# LPC408x_7x register map
File version: 0.7
CPU: CM4 r0p0, little endian, no MPU, no FPU, 3 interrupt priority bits
Registers are 32-bit, read-write, reset 0x0 unless marked. A register's access mark holds for its fields unless they carry their own. Offsets are from the block's base; [hi:lo] are bit positions; {n}, {i} and the like mark numbered series; 'fields as' and 'values as' point back to an identical list.

## IOCON (part 2 of 2) — IOCON pin configuration
Base 0x4002C000
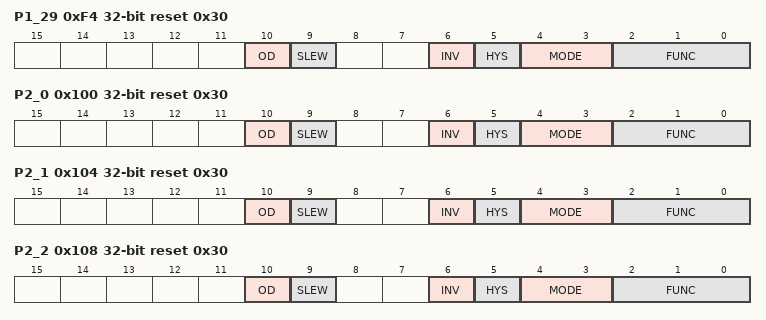
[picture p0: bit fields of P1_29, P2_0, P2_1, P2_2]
0xF4 P1_29 reset 0x30 — I/O configuration register for pin P1[29]
  [10] OD — Open-drain mode.
    0=DISABLE_; 1=OPEN_DRAIN_MODE_ENAB (Open-drain mode enabled. This is not a true open-drain mode. Input cannot be pulled up above VDD.)
  [9] SLEW — Driver slew rate
    0=STANDARD (Standard mode, output slew rate control is enabled. More outputs can be switched simultaneously.); 1=FAST (Fast mode, slew rate control is disabled. Refer to the appropriate specific device data sheet for details.)
  [6] INV — Invert input
    0=INPUT_NOT_INVERTED_ (Input not inverted (HIGH on pin reads as 1, LOW on pin reads as 0).); 1=INPUT_INVERTED_HIGH (Input inverted (HIGH on pin reads as 0, LOW on pin reads as 1).)
  [5] HYS — Hysteresis.
    0=DISABLE_; 1=ENABLE_
  [4:3] MODE — Selects function mode (on-chip pull-up/pull-down resistor control).
    0=INACTIVE_NO_PULL_DO (Inactive (no pull-down/pull-up resistor enabled).); 1=PULL_DOWN_RESISTOR_E (Pull-down resistor enabled.); 2=PULL_UP_RESISTOR_ENA (Pull-up resistor enabled.); 3=REPEATER_MODE_
  [2:0] FUNC — Selects pin function for pin P1[29]
    0=P1_29 (General purpose digital input/output pin.); 1=USB_SDA1 (USB port 1 I2C serial data (OTG transceiver).); 2=PWM1_CAP1 (Capture input for PWM1, channel 1.); 3=T0_MAT1 (Match output for Timer 0, channel 1.); 4=MC_2B (Motor control PWM channel 2, output B.); 5=U4_TXD (Transmitter output for USART4 (input/output in smart card mode).); 6=LCD_VD_15 (LCD data.); 7=LCD_VD_23 (LCD data.)
0xF8 P1_30 reset not defined — I/O configuration register for pin P1[30]
  [2:0] FUNC — Selects pin function for pin P1[30]
    0=P1_30 (General purpose digital input/output pin.); 1=USB_PWRD2 (Power Status for USB port 2.); 2=USB_VBUS (Monitors the presence of USB bus power.This signal must be HIGH for USB reset to occur.); 3=ADC0_IN_4 (A/D converter 0, input 4. When configured as an ADC input, the digital function of the pin must be disabled.); 4=I2C0_SDA (I2C0 data input/output (this pin does not use a specialized I2C pad.); 5=U3_OE (RS-485/EIA-485 output enable signal for UART3.)
0xFC P1_31 reset not defined — I/O configuration register for pin P1[31]
  [2:0] FUNC — Selects pin function for pin P1[31]
    0=P1_31 (General purpose digital input/output pin.); 1=USB_OVRCR2 (Over-Current status for USB port 2.); 2=SSP1_SCK (Serial Clock for SSP1.); 3=ADC0_IN_5 (A/D converter 0, input 5. When configured as an ADC input, the digital function of the pin must be disabled.); 4=I2C0_SCL (I2C0 clock input/output (this pin does not use a specialized I2C pad.)
0x100 P2_0 reset 0x30 — I/O configuration register for pin P2[0]
  [10] OD — Open-drain mode.
    values as P1_29.OD
  [9] SLEW — Driver slew rate
    values as P1_29.SLEW
  [6] INV — Invert input
    values as P1_29.INV
  [5] HYS — Hysteresis.
    0=DISABLE_; 1=ENABLE_
  [4:3] MODE — Selects function mode (on-chip pull-up/pull-down resistor control).
    values as P1_29.MODE
  [2:0] FUNC — Selects pin function for pin P2[0]
    0=P2_0 (General purpose digital input/output pin.); 1=PWM1_1 (Pulse Width Modulator 1, channel 1 output.); 2=U1_TXD (Transmitter output for UART1.); 7=LCD_PWR (LCD panel power enable.)
0x104 P2_1 reset 0x30 — I/O configuration register for pin P2[1]
  [10] OD — Open-drain mode.
    values as P1_29.OD
  [9] SLEW — Driver slew rate
    values as P1_29.SLEW
  [6] INV — Invert input
    values as P1_29.INV
  [5] HYS — Hysteresis.
    0=DISABLE_; 1=ENABLE_
  [4:3] MODE — Selects function mode (on-chip pull-up/pull-down resistor control).
    values as P1_29.MODE
  [2:0] FUNC — Selects pin function for pin P2[1]
    0=P2_1 (General purpose digital input/output pin.); 1=PWM1_2 (Pulse Width Modulator 1, channel 2 output.); 2=U1_RXD (Receiver input for UART1.); 7=LCD_LE (Line end signal.)
0x108 P2_2 reset 0x30 — I/O configuration register for pin P2[2]
  [10] OD — Open-drain mode.
    values as P1_29.OD
  [9] SLEW — Driver slew rate
    values as P1_29.SLEW
  [6] INV — Invert input
    values as P1_29.INV
  [5] HYS — Hysteresis.
    0=DISABLE_; 1=ENABLE_
  [4:3] MODE — Selects function mode (on-chip pull-up/pull-down resistor control).
    values as P1_29.MODE
  [2:0] FUNC — Selects pin function for pin P2[2]
    0=P2_2 (General purpose digital input/output pin.); 1=PWM1_3 (Pulse Width Modulator 1, channel 3 output.); 2=U1_CTS (Clear to Send input for UART1.); 3=T2_MAT3 (Match output for Timer 2, channel 3.); 5=TRACEDATA_3 (Trace data, bit 3.); 7=LCD_DCLK (LCD panel clock.)
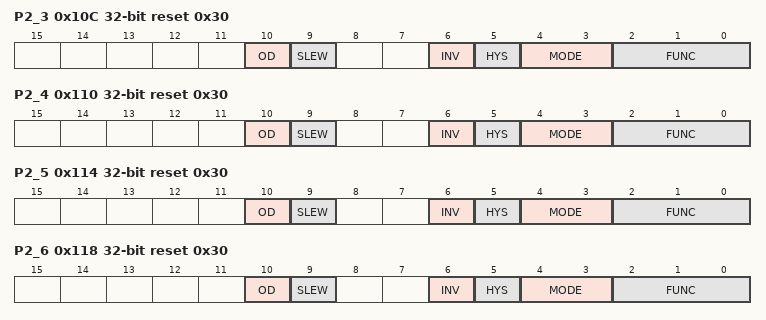
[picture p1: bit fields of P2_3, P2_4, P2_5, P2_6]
0x10C P2_3 reset 0x30 — I/O configuration register for pin P2[3]
  [10] OD — Open-drain mode.
    values as P1_29.OD
  [9] SLEW — Driver slew rate
    values as P1_29.SLEW
  [6] INV — Invert input
    values as P1_29.INV
  [5] HYS — Hysteresis.
    0=DISABLE_; 1=ENABLE_
  [4:3] MODE — Selects function mode (on-chip pull-up/pull-down resistor control).
    values as P1_29.MODE
  [2:0] FUNC — Selects pin function for pin P2[3]
    0=P2_3 (General purpose digital input/output pin.); 1=PWM1_4 (Pulse Width Modulator 1, channel 4 output.); 2=U1_DCD (Data Carrier Detect input for UART1.); 3=T2_MAT2 (Match output for Timer 2, channel 2.); 5=TRACEDATA_2 (Trace data, bit 2.); 7=LCD_FP (Frame pulse (STN). Vertical synchronization pulse (TFT).)
0x110 P2_4 reset 0x30 — I/O configuration register for pin P2[4]
  [10] OD — Open-drain mode.
    values as P1_29.OD
  [9] SLEW — Driver slew rate
    values as P1_29.SLEW
  [6] INV — Invert input
    values as P1_29.INV
  [5] HYS — Hysteresis.
    0=DISABLE_; 1=ENABLE_
  [4:3] MODE — Selects function mode (on-chip pull-up/pull-down resistor control).
    values as P1_29.MODE
  [2:0] FUNC — Selects pin function for pin P2[4]
    0=P2_4 (General purpose digital input/output pin.); 1=PWM1_5 (Pulse Width Modulator 1, channel 5 output.); 2=U1_DSR (Data Set Ready input for UART1.); 3=T2_MAT1 (Match output for Timer 2, channel 1.); 5=TRACEDATA_1 (Trace data, bit 1.); 7=LCD_ENAB_M (STN AC bias drive or TFT data enable output.)
0x114 P2_5 reset 0x30 — I/O configuration register for pin P2[5]
  [10] OD — Open-drain mode.
    values as P1_29.OD
  [9] SLEW — Driver slew rate
    values as P1_29.SLEW
  [6] INV — Invert input
    values as P1_29.INV
  [5] HYS — Hysteresis.
    0=DISABLE_; 1=ENABLE_
  [4:3] MODE — Selects function mode (on-chip pull-up/pull-down resistor control).
    values as P1_29.MODE
  [2:0] FUNC — Selects pin function for pin P2[5]
    0=P2_5 (General purpose digital input/output pin.); 1=PWM1_6 (Pulse Width Modulator 1, channel 6 output.); 2=U1_DTR (Data Terminal Ready output for UART1. Can also be configured to be an RS-485/EIA-485 output enable signal for UART1.); 3=T2_MAT0 (Match output for Timer 2, channel 0.); 5=TRACEDATA_0 (Trace data, bit 0.); 7=LCD_LP (Line synchronization pulse (STN). Horizontal synchronization pulse (TFT).)
0x118 P2_6 reset 0x30 — I/O configuration register for pin P2[6]
  [10] OD — Open-drain mode.
    values as P1_29.OD
  [9] SLEW — Driver slew rate
    values as P1_29.SLEW
  [6] INV — Invert input
    values as P1_29.INV
  [5] HYS — Hysteresis.
    0=DISABLE_; 1=ENABLE_
  [4:3] MODE — Selects function mode (on-chip pull-up/pull-down resistor control).
    values as P1_29.MODE
  [2:0] FUNC — Selects pin function for pin P2[6]
    0=P2_6 (General purpose digital input/output pin.); 1=PWM1_CAP0 (Capture input for PWM1, channel 0.); 2=U1_RI (Ring Indicator input for UART1.); 3=T2_CAP0 (Capture input for Timer 2, channel 0.); 4=U2_OE (RS-485/EIA-485 output enable signal for UART2.); 5=TRACECLK (Trace clock.); 6=LCD_VD_0 (LCD data.); 7=LCD_VD_4 (LCD data.)
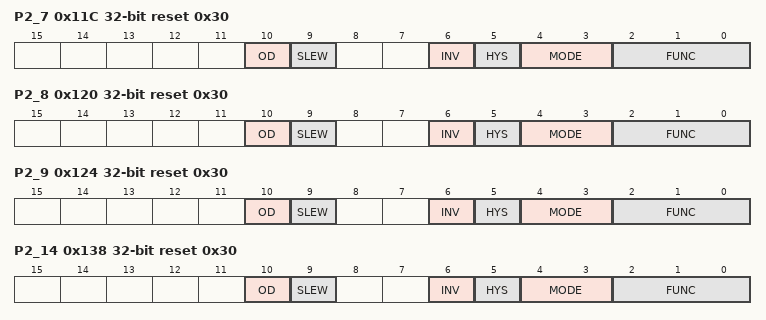
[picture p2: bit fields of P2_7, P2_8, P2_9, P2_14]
0x11C P2_7 reset 0x30 — I/O configuration register for pin P2[7]
  [10] OD — Open-drain mode.
    values as P1_29.OD
  [9] SLEW — Driver slew rate
    values as P1_29.SLEW
  [6] INV — Invert input
    values as P1_29.INV
  [5] HYS — Hysteresis.
    0=DISABLE_; 1=ENABLE_
  [4:3] MODE — Selects function mode (on-chip pull-up/pull-down resistor control).
    values as P1_29.MODE
  [2:0] FUNC — Selects pin function for pin P2[7]
    0=P2_7 (General purpose digital input/output pin.); 1=CAN_RD2 (CAN2 receiver input.); 2=U1_RTS (Request to Send output for UART1. Can also be configured to be an RS-485/EIA-485 output enable signal for UART1.); 5=SPIFI_CS (Chip select output for SPIFI.); 6=LCD_VD_1 (LCD data.); 7=LCD_VD_5 (LCD data.)
0x120 P2_8 reset 0x30 — I/O configuration register for pin P2[8]
  [10] OD — Open-drain mode.
    values as P1_29.OD
  [9] SLEW — Driver slew rate
    values as P1_29.SLEW
  [6] INV — Invert input
    values as P1_29.INV
  [5] HYS — Hysteresis.
    0=DISABLE_; 1=ENABLE_
  [4:3] MODE — Selects function mode (on-chip pull-up/pull-down resistor control).
    values as P1_29.MODE
  [2:0] FUNC — Selects pin function for pin P2[8]
    0=P2_8 (General purpose digital input/output pin.); 1=CAN_TD2 (CAN2 transmitter output.); 2=U2_TXD (Transmitter output for UART2.); 3=U1_CTS (Clear to Send input for UART1.); 4=ENET_MDC (Ethernet MIIM clock.); 6=LCD_VD_2 (LCD data.); 7=LCD_VD_6 (LCD data.)
0x124 P2_9 reset 0x30 — I/O configuration register for pin P2[9]
  [10] OD — Open-drain mode.
    values as P1_29.OD
  [9] SLEW — Driver slew rate
    values as P1_29.SLEW
  [6] INV — Invert input
    values as P1_29.INV
  [5] HYS — Hysteresis.
    0=DISABLE_; 1=ENABLE_
  [4:3] MODE — Selects function mode (on-chip pull-up/pull-down resistor control).
    values as P1_29.MODE
  [2:0] FUNC — Selects pin function for pin P2[9]
    0=P2_9 (General purpose digital input/output pin.); 1=USB_CONNECT1 (USB1 SoftConnect control. Signal used to switch an external 1.5 kW resistor under the software control. Used with the SoftConnect USB feature.); 2=U2_RXD (Receiver input for UART2.); 3=U4_RXD (Receiver input for USART4.); 4=ENET_MDIO (Ethernet MIIM data input and output.); 6=LCD_VD_3 (LCD data.); 7=LCD_VD_7 (LCD data.)
0x128 P2_10 reset not defined — I/O configuration register for pin P2[10]
  [2:0] FUNC — Selects pin function for pin P2[10]
    0=P2_10 (General purpose digital input/output pin. This pin includes a 5 ns input glitch filter.A LOW on this pin while RESET is LOW forces the on-chip boot loader to take over control of the part after a reset and go into ISP mode.); 1=EINT0 (External interrupt 0 input.); 2=NMI (Non-maskable interrupt input.)
0x12C P2_11 reset not defined — I/O configuration register for pin P2[11]
  [2:0] FUNC — Selects pin function for pin P2[11]
    0=P2_11 (General purpose digital input/output pin. This pin includes a 5 ns input glitch filter.); 1=EINT1 (External interrupt 1 input.); 2=SD_DAT_1 (Data line 1 for SD card interface.); 3=I2S_TX_SCK (Transmit Clock. It is driven by the master and received by the slave. Corresponds to the signal SCK in the I2S-bus specification.); 7=LCD_CLKIN (LCD clock.)
0x130 P2_12 reset not defined — I/O configuration register for pin P2[12]
  [2:0] FUNC — Selects pin function for pin P2[12]
    0=P2_12 (General purpose digital input/output pin. This pin includes a 5 ns input glitch filter.); 1=EINT2 (External interrupt 2 input.); 2=SD_DAT_2 (Data line 2 for SD card interface.); 3=I2S_TX_WS (Transmit Word Select. It is driven by the master and received by the slave. Corresponds to the signal WS in the I2S-bus specification.); 4=LCD_VD_4 (LCD data.); 5=LCD_VD_3 (LCD data.); 6=LCD_VD_8 (LCD data.); 7=LCD_VD_18 (LCD data.)
0x134 P2_13 reset not defined — I/O configuration register for pin P2[13]
  [2:0] FUNC — Selects pin function for pin P2[13]
    0=P2_13 (General purpose digital input/output pin. This pin includes a 5 ns input glitch filter.); 1=EINT3 (External interrupt 3 input.); 2=SD_DAT_3 (Data line 3 for SD card interface.); 3=I2S_TX_SDA (Transmit data. It is driven by the transmitter and read by the receiver. Corresponds to the signal SD in the I2S-bus specification.); 5=LCD_VD_5 (LCD data.); 6=LCD_VD_9 (LCD data.); 7=LCD_VD_19 (LCD data.)
0x138 P2_14 reset 0x30 — I/O configuration register for pin P2[14]
  [10] OD — Open-drain mode.
    values as P1_29.OD
  [9] SLEW — Driver slew rate
    values as P1_29.SLEW
  [6] INV — Invert input
    values as P1_29.INV
  [5] HYS — Hysteresis.
    0=DISABLE_; 1=ENABLE_
  [4:3] MODE — Selects function mode (on-chip pull-up/pull-down resistor control).
    values as P1_29.MODE
  [2:0] FUNC — Selects pin function for pin P2[14]
    0=P2_14 (General purpose digital input/output pin.); 1=EMC_CS2 (LOW active Chip Select 2 signal.); 2=I2C1_SDA (I2C1 data input/output (this pin does not use a specialized I2C pad).); 3=T2_CAP0 (Capture input for Timer 2, channel 0.)
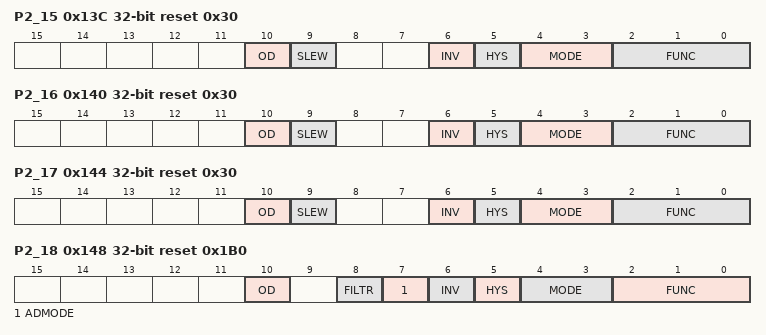
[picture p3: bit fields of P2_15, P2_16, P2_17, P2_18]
0x13C P2_15 reset 0x30 — I/O configuration register for pin P2[15]
  [10] OD — Open-drain mode.
    values as P1_29.OD
  [9] SLEW — Driver slew rate
    values as P1_29.SLEW
  [6] INV — Invert input
    values as P1_29.INV
  [5] HYS — Hysteresis.
    0=DISABLE_; 1=ENABLE_
  [4:3] MODE — Selects function mode (on-chip pull-up/pull-down resistor control).
    values as P1_29.MODE
  [2:0] FUNC — Selects pin function for pin P2[15]
    0=P2_15 (General purpose digital input/output pin.); 1=EMC_CS3 (LOW active Chip Select 3 signal.); 2=I2C1_SCL (I2C1 clock input/output (this pin does not use a specialized I2C pad).); 3=T2_CAP1 (Capture input for Timer 2, channel 1.)
0x140 P2_16 reset 0x30 — I/O configuration register for pin P2[16]
  [10] OD — Open-drain mode.
    values as P1_29.OD
  [9] SLEW — Driver slew rate
    values as P1_29.SLEW
  [6] INV — Invert input
    values as P1_29.INV
  [5] HYS — Hysteresis.
    0=DISABLE_; 1=ENABLE_
  [4:3] MODE — Selects function mode (on-chip pull-up/pull-down resistor control).
    values as P1_29.MODE
  [2:0] FUNC — Selects pin function for pin P2[16]
    0=P2_16 (General purpose digital input/output pin.); 1=EMC_CAS (LOW active SDRAM Column Address Strobe.)
0x144 P2_17 reset 0x30 — I/O configuration register for pin P2[17]
  [10] OD — Open-drain mode.
    values as P1_29.OD
  [9] SLEW — Driver slew rate
    values as P1_29.SLEW
  [6] INV — Invert input
    values as P1_29.INV
  [5] HYS — Hysteresis.
    0=DISABLE_; 1=ENABLE_
  [4:3] MODE — Selects function mode (on-chip pull-up/pull-down resistor control).
    values as P1_29.MODE
  [2:0] FUNC — Selects pin function for pin P2[17]
    0=P2_17 (General purpose digital input/output pin.); 1=EMC_RAS (LOW active SDRAM Row Address Strobe.)
0x148 P2_18 reset 0x1B0 — I/O configuration register for pin P2[18]
  [10] OD — Open-drain mode.
    0=DISABLE_; 1=OPEN_DRAIN_MODE_ENAB (Open-drain mode enabled. This is not a true open-drain mode.)
  [8] FILTR — Selects 10 ns input glitch filter.
    0=FILTER_DISABLED_; 1=FILTER_ENABLED_
  [7] ADMODE — Selects Analog/Digital mode.
    0=ANALOG_INPUT_MODE_; 1=DIGITAL_FUNCTIONAL_M (Digital functional mode.)
  [6] INV — Invert input
    values as P1_29.INV
  [5] HYS — Hysteresis.
    0=DISABLE_; 1=ENABLE_
  [4:3] MODE — Selects function mode (on-chip pull-up/pull-down resistor control).
    values as P1_29.MODE
  [2:0] FUNC — Selects pin function for pin P2[18]
    0=P2_18 (General purpose digital input/output pin.); 1=EMC_CLK_0 (SDRAM clock 0.)
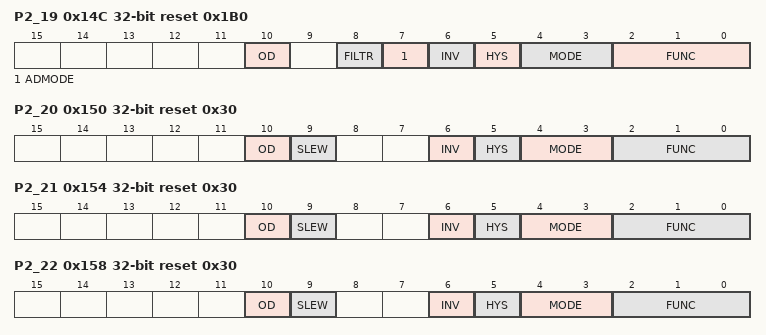
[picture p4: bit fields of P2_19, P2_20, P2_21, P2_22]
0x14C P2_19 reset 0x1B0 — I/O configuration register for pin P2[19]
  [10] OD — Open-drain mode.
    values as P2_18.OD
  [8] FILTR — Selects 10 ns input glitch filter.
    0=FILTER_DISABLED_; 1=FILTER_ENABLED_
  [7] ADMODE — Selects Analog/Digital mode.
    values as P2_18.ADMODE
  [6] INV — Invert input
    values as P1_29.INV
  [5] HYS — Hysteresis.
    0=DISABLE_; 1=ENABLE_
  [4:3] MODE — Selects function mode (on-chip pull-up/pull-down resistor control).
    values as P1_29.MODE
  [2:0] FUNC — Selects pin function for pin P2[19]
    0=P2_19 (General purpose digital input/output pin.); 1=EMC_CLK_1 (SDRAM clock 1.)
0x150 P2_20 reset 0x30 — I/O configuration register for pin P2[20]
  [10] OD — Open-drain mode.
    values as P1_29.OD
  [9] SLEW — Driver slew rate
    values as P1_29.SLEW
  [6] INV — Invert input
    values as P1_29.INV
  [5] HYS — Hysteresis.
    0=DISABLE_; 1=ENABLE_
  [4:3] MODE — Selects function mode (on-chip pull-up/pull-down resistor control).
    values as P1_29.MODE
  [2:0] FUNC — Selects pin function for pin P2[20]
    0=P2_20 (General purpose digital input/output pin.); 1=EMC_DYCS0 (SDRAM chip select 0.)
0x154 P2_21 reset 0x30 — I/O configuration register for pin P2[21]
  [10] OD — Open-drain mode.
    values as P1_29.OD
  [9] SLEW — Driver slew rate
    values as P1_29.SLEW
  [6] INV — Invert input
    values as P1_29.INV
  [5] HYS — Hysteresis.
    0=DISABLE_; 1=ENABLE_
  [4:3] MODE — Selects function mode (on-chip pull-up/pull-down resistor control).
    values as P1_29.MODE
  [2:0] FUNC — Selects pin function for pin P2[21]
    0=P2_21 (General purpose digital input/output pin.); 1=EMC_DYCS1 (SDRAM chip select 1.)
0x158 P2_22 reset 0x30 — I/O configuration register for pin P2[22]
  [10] OD — Open-drain mode.
    values as P1_29.OD
  [9] SLEW — Driver slew rate
    values as P1_29.SLEW
  [6] INV — Invert input
    values as P1_29.INV
  [5] HYS — Hysteresis.
    0=DISABLE_; 1=ENABLE_
  [4:3] MODE — Selects function mode (on-chip pull-up/pull-down resistor control).
    values as P1_29.MODE
  [2:0] FUNC — Selects pin function for pin P2[22]
    0=P2_22 (General purpose digital input/output pin.); 1=EMC_DYCS2 (SDRAM chip select 2.); 2=SSP0_SCK (Serial clock for SSP0.); 3=T3_CAP0 (Capture input for Timer 3, channel 0.)
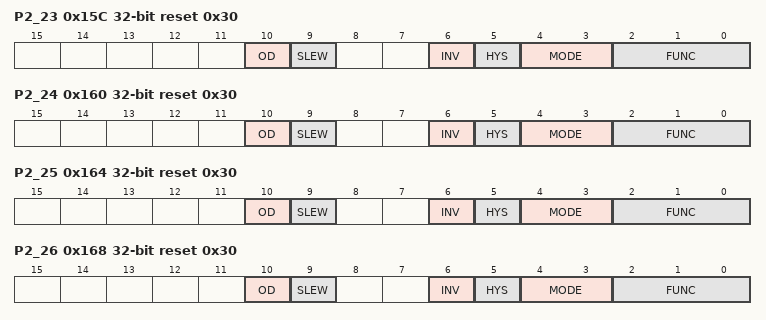
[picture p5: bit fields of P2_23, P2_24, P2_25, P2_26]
0x15C P2_23 reset 0x30 — I/O configuration register for pin P2[23]
  [10] OD — Open-drain mode.
    values as P1_29.OD
  [9] SLEW — Driver slew rate
    values as P1_29.SLEW
  [6] INV — Invert input
    values as P1_29.INV
  [5] HYS — Hysteresis.
    0=DISABLE_; 1=ENABLE_
  [4:3] MODE — Selects function mode (on-chip pull-up/pull-down resistor control).
    values as P1_29.MODE
  [2:0] FUNC — Selects pin function for pin P2[23]
    0=P2_23 (General purpose digital input/output pin.); 1=EMC_DYCS3 (SDRAM chip select 3.); 2=SSP0_SSEL (Slave Select for SSP0.); 3=T3_CAP1 (Capture input for Timer 3, channel 1.)
0x160 P2_24 reset 0x30 — I/O configuration register for pin P2[24]
  [10] OD — Open-drain mode.
    values as P1_29.OD
  [9] SLEW — Driver slew rate
    values as P1_29.SLEW
  [6] INV — Invert input
    values as P1_29.INV
  [5] HYS — Hysteresis.
    0=DISABLE_; 1=ENABLE_
  [4:3] MODE — Selects function mode (on-chip pull-up/pull-down resistor control).
    values as P1_29.MODE
  [2:0] FUNC — Selects pin function for pin P2[24]
    0=P2_24 (General purpose digital input/output pin.); 1=EMC_CKE0 (SDRAM clock enable 0.)
0x164 P2_25 reset 0x30 — I/O configuration register for pin P2[25]
  [10] OD — Open-drain mode.
    values as P1_29.OD
  [9] SLEW — Driver slew rate
    values as P1_29.SLEW
  [6] INV — Invert input
    values as P1_29.INV
  [5] HYS — Hysteresis.
    0=DISABLE_; 1=ENABLE_
  [4:3] MODE — Selects function mode (on-chip pull-up/pull-down resistor control).
    values as P1_29.MODE
  [2:0] FUNC — Selects pin function for pin P2[25]
    0=P2_25 (General purpose digital input/output pin.); 1=EMC_CKE1 (SDRAM clock enable 1.)
0x168 P2_26 reset 0x30 — I/O configuration register for pin P2[26]
  [10] OD — Open-drain mode.
    values as P1_29.OD
  [9] SLEW — Driver slew rate
    values as P1_29.SLEW
  [6] INV — Invert input
    values as P1_29.INV
  [5] HYS — Hysteresis.
    0=DISABLE_; 1=ENABLE_
  [4:3] MODE — Selects function mode (on-chip pull-up/pull-down resistor control).
    values as P1_29.MODE
  [2:0] FUNC — Selects pin function for pin P2[26]
    0=P2_26 (General purpose digital input/output pin.); 1=EMC_CKE2 (SDRAM clock enable 2.); 2=SSP0_MISO (Master In Slave Out for SSP0.); 3=T3_MAT0 (Match output for Timer 3, channel 0.)
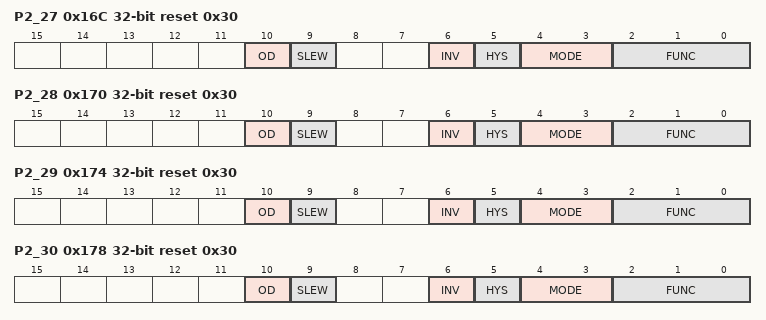
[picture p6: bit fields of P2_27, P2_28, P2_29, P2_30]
0x16C P2_27 reset 0x30 — I/O configuration register for pin P2[27]
  [10] OD — Open-drain mode.
    values as P1_29.OD
  [9] SLEW — Driver slew rate
    values as P1_29.SLEW
  [6] INV — Invert input
    values as P1_29.INV
  [5] HYS — Hysteresis.
    0=DISABLE_; 1=ENABLE_
  [4:3] MODE — Selects function mode (on-chip pull-up/pull-down resistor control).
    values as P1_29.MODE
  [2:0] FUNC — Selects pin function for pin P2[27]
    0=P2_27 (General purpose digital input/output pin.); 1=EMC_CKE3 (SDRAM clock enable 3.); 2=SSP0_MOSI (Master Out Slave In for SSP0.); 3=T3_MAT1 (Match output for Timer 3, channel 1.)
0x170 P2_28 reset 0x30 — I/O configuration register for pin P2[28]
  [10] OD — Open-drain mode.
    values as P1_29.OD
  [9] SLEW — Driver slew rate
    values as P1_29.SLEW
  [6] INV — Invert input
    values as P1_29.INV
  [5] HYS — Hysteresis.
    0=DISABLE_; 1=ENABLE_
  [4:3] MODE — Selects function mode (on-chip pull-up/pull-down resistor control).
    values as P1_29.MODE
  [2:0] FUNC — Selects pin function for pin P2[28]
    0=P2_28 (General purpose digital input/output pin.); 1=EMC_DQM0 (Data mask 0 used with SDRAM and static devices.)
0x174 P2_29 reset 0x30 — I/O configuration register for pin P2[29]
  [10] OD — Open-drain mode.
    values as P1_29.OD
  [9] SLEW — Driver slew rate
    values as P1_29.SLEW
  [6] INV — Invert input
    values as P1_29.INV
  [5] HYS — Hysteresis.
    0=DISABLE_; 1=ENABLE_
  [4:3] MODE — Selects function mode (on-chip pull-up/pull-down resistor control).
    values as P1_29.MODE
  [2:0] FUNC — Selects pin function for pin P2[29]
    0=P2_29 (General purpose digital input/output pin.); 1=EMC_DQM1 (Data mask 1 used with SDRAM and static devices.)
0x178 P2_30 reset 0x30 — I/O configuration register for pin P2[30]
  [10] OD — Open-drain mode.
    values as P1_29.OD
  [9] SLEW — Driver slew rate
    values as P1_29.SLEW
  [6] INV — Invert input
    values as P1_29.INV
  [5] HYS — Hysteresis.
    0=DISABLE_; 1=ENABLE_
  [4:3] MODE — Selects function mode (on-chip pull-up/pull-down resistor control).
    values as P1_29.MODE
  [2:0] FUNC — Selects pin function for pin P2[30]
    0=P2_30 (General purpose digital input/output pin.); 1=EMC_DQM2 (Data mask 2 used with SDRAM and static devices.); 2=I2C2_SDA (I2C2 data input/output (this pin does not use a specialized I2C pad).); 3=T3_MAT2 (Match output for Timer 3, channel 2.)
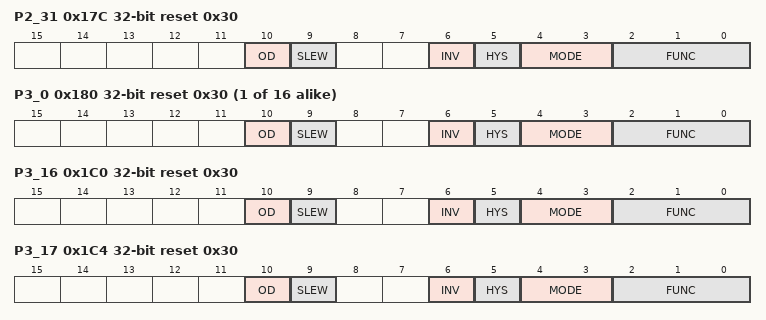
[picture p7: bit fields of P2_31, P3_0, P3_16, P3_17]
0x17C P2_31 reset 0x30 — I/O configuration register for pin P2[31]
  [10] OD — Open-drain mode.
    values as P1_29.OD
  [9] SLEW — Driver slew rate
    values as P1_29.SLEW
  [6] INV — Invert input
    values as P1_29.INV
  [5] HYS — Hysteresis.
    0=DISABLE_; 1=ENABLE_
  [4:3] MODE — Selects function mode (on-chip pull-up/pull-down resistor control).
    values as P1_29.MODE
  [2:0] FUNC — Selects pin function for pin P2[31]
    0=P2_31 (General purpose digital input/output pin.); 1=EMC_DQM3 (Data mask 3 used with SDRAM and static devices.); 2=I2C2_SCL (I2C2 clock input/output (this pin does not use a specialized I2C pad).); 3=T3_MAT3 (Match output for Timer 3, channel 3.)
{0x180+4i} P3_{i} reset 0x30 (i=0..15) — I/O configuration register for pin P3[{i}]
  [10] OD — Open-drain mode.
    values as P1_29.OD
  [9] SLEW — Driver slew rate
    values as P1_29.SLEW
  [6] INV — Invert input
    values as P1_29.INV
  [5] HYS — Hysteresis.
    0=DISABLE_; 1=ENABLE_
  [4:3] MODE — Selects function mode (on-chip pull-up/pull-down resistor control).
    values as P1_29.MODE
  [2:0] FUNC — Selects pin function for pin P3[{i}]
    0=P3_{i} (General purpose digital input/output pin.); 1=EMC_D_{i} (External memory data line {i}.)
0x1C0 P3_16 reset 0x30 — I/O configuration register for pin P3[16]
  [10] OD — Open-drain mode.
    values as P1_29.OD
  [9] SLEW — Driver slew rate
    values as P1_29.SLEW
  [6] INV — Invert input
    values as P1_29.INV
  [5] HYS — Hysteresis.
    0=DISABLE_; 1=ENABLE_
  [4:3] MODE — Selects function mode (on-chip pull-up/pull-down resistor control).
    values as P1_29.MODE
  [2:0] FUNC — Selects pin function for pin P3[16]
    0=P3_16 (General purpose digital input/output pin.); 1=EMC_D_16 (External memory data line 16.); 2=PWM0_1 (Pulse Width Modulator 0, output 1.); 3=U1_TXD (Transmitter output for UART1.)
0x1C4 P3_17 reset 0x30 — I/O configuration register for pin P3[17]
  [10] OD — Open-drain mode.
    values as P1_29.OD
  [9] SLEW — Driver slew rate
    values as P1_29.SLEW
  [6] INV — Invert input
    values as P1_29.INV
  [5] HYS — Hysteresis.
    0=DISABLE_; 1=ENABLE_
  [4:3] MODE — Selects function mode (on-chip pull-up/pull-down resistor control).
    values as P1_29.MODE
  [2:0] FUNC — Selects pin function for pin P3[17]
    0=P3_17 (General purpose digital input/output pin.); 1=EMC_D_17 (External memory data line 17.); 2=PWM0_2 (Pulse Width Modulator 0, output 2.); 3=U1_RXD (Receiver input for UART1.)
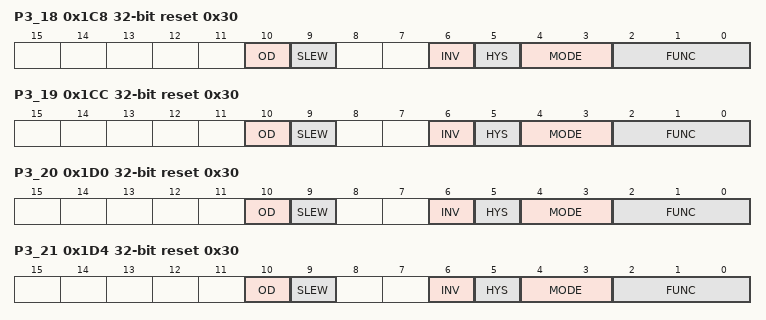
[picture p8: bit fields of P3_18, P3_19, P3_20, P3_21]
0x1C8 P3_18 reset 0x30 — I/O configuration register for pin P3[18]
  [10] OD — Open-drain mode.
    values as P1_29.OD
  [9] SLEW — Driver slew rate
    values as P1_29.SLEW
  [6] INV — Invert input
    values as P1_29.INV
  [5] HYS — Hysteresis.
    0=DISABLE_; 1=ENABLE_
  [4:3] MODE — Selects function mode (on-chip pull-up/pull-down resistor control).
    values as P1_29.MODE
  [2:0] FUNC — Selects pin function for pin P3[18]
    0=P3_18 (General purpose digital input/output pin.); 1=EMC_D_18 (External memory data line 18.); 2=PWM0_3 (Pulse Width Modulator 0, output 3.); 3=U1_CTS (Clear to Send input for UART1.)
0x1CC P3_19 reset 0x30 — I/O configuration register for pin P3[19]
  [10] OD — Open-drain mode.
    values as P1_29.OD
  [9] SLEW — Driver slew rate
    values as P1_29.SLEW
  [6] INV — Invert input
    values as P1_29.INV
  [5] HYS — Hysteresis.
    0=DISABLE_; 1=ENABLE_
  [4:3] MODE — Selects function mode (on-chip pull-up/pull-down resistor control).
    values as P1_29.MODE
  [2:0] FUNC — Selects pin function for pin P3[19]
    0=P3_19 (General purpose digital input/output pin.); 1=EMC_D_19 (External memory data line 19.); 2=PWM0_4 (Pulse Width Modulator 0, output 4.); 3=U1_DCD (Data Carrier Detect input for UART1.)
0x1D0 P3_20 reset 0x30 — I/O configuration register for pin P3[20]
  [10] OD — Open-drain mode.
    values as P1_29.OD
  [9] SLEW — Driver slew rate
    values as P1_29.SLEW
  [6] INV — Invert input
    values as P1_29.INV
  [5] HYS — Hysteresis.
    0=DISABLE_; 1=ENABLE_
  [4:3] MODE — Selects function mode (on-chip pull-up/pull-down resistor control).
    values as P1_29.MODE
  [2:0] FUNC — Selects pin function for pin P3[20]
    0=P3_20 (General purpose digital input/output pin.); 1=EMC_D_20 (External memory data line 20.); 2=PWM0_5 (Pulse Width Modulator 0, output 5.); 3=U1_DSR (Data Set Ready input for UART1.)
0x1D4 P3_21 reset 0x30 — I/O configuration register for pin P3[21]
  [10] OD — Open-drain mode.
    values as P1_29.OD
  [9] SLEW — Driver slew rate
    values as P1_29.SLEW
  [6] INV — Invert input
    values as P1_29.INV
  [5] HYS — Hysteresis.
    0=DISABLE_; 1=ENABLE_
  [4:3] MODE — Selects function mode (on-chip pull-up/pull-down resistor control).
    values as P1_29.MODE
  [2:0] FUNC — Selects pin function for pin P3[21]
    0=P3_21 (General purpose digital input/output pin.); 1=EMC_D_21 (External memory data line 21.); 2=PWM0_6 (Pulse Width Modulator 0, output 6.); 3=U1_DTR (Data Terminal Ready output for UART1. Can also be configured to be an RS-485/EIA-485 output enable signal for UART1.)
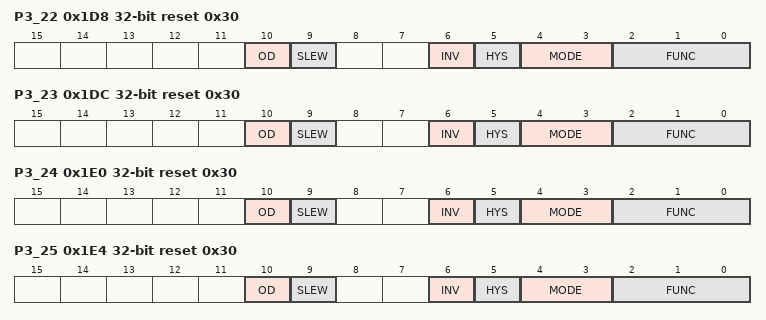
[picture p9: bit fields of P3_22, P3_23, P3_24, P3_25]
0x1D8 P3_22 reset 0x30 — I/O configuration register for pin P3[22]
  [10] OD — Open-drain mode.
    values as P1_29.OD
  [9] SLEW — Driver slew rate
    values as P1_29.SLEW
  [6] INV — Invert input
    values as P1_29.INV
  [5] HYS — Hysteresis.
    0=DISABLE_; 1=ENABLE_
  [4:3] MODE — Selects function mode (on-chip pull-up/pull-down resistor control).
    values as P1_29.MODE
  [2:0] FUNC — Selects pin function for pin P3[22]
    0=P3_22 (General purpose digital input/output pin.); 1=EMC_D_22 (External memory data line 22.); 2=PWM0_CAP0 (Capture input for PWM0, channel 0.); 3=U1_RI (Ring Indicator input for UART1.)
0x1DC P3_23 reset 0x30 — I/O configuration register for pin P3[23]
  [10] OD — Open-drain mode.
    values as P1_29.OD
  [9] SLEW — Driver slew rate
    values as P1_29.SLEW
  [6] INV — Invert input
    values as P1_29.INV
  [5] HYS — Hysteresis.
    0=DISABLE_; 1=ENABLE_
  [4:3] MODE — Selects function mode (on-chip pull-up/pull-down resistor control).
    values as P1_29.MODE
  [2:0] FUNC — Selects pin function for pin P3[23]
    0=P3_23 (General purpose digital input/output pin.); 1=EMC_D_23 (External memory data line 23.); 2=PWM1_CAP0 (Capture input for PWM1, channel 0.); 3=T0_CAP0 (Capture input for Timer 0, channel 0.)
0x1E0 P3_24 reset 0x30 — I/O configuration register for pin P3[24]
  [10] OD — Open-drain mode.
    values as P1_29.OD
  [9] SLEW — Driver slew rate
    values as P1_29.SLEW
  [6] INV — Invert input
    values as P1_29.INV
  [5] HYS — Hysteresis.
    0=DISABLE_; 1=ENABLE_
  [4:3] MODE — Selects function mode (on-chip pull-up/pull-down resistor control).
    values as P1_29.MODE
  [2:0] FUNC — Selects pin function for pin P3[24]
    0=P3_24 (General purpose digital input/output pin.); 1=EMC_D_24 (External memory data line 24.); 2=PWM1_1 (Pulse Width Modulator 1, output 1.); 3=T0_CAP1 (Capture input for Timer 0, channel 1.)
0x1E4 P3_25 reset 0x30 — I/O configuration register for pin P3[25]
  [10] OD — Open-drain mode.
    values as P1_29.OD
  [9] SLEW — Driver slew rate
    values as P1_29.SLEW
  [6] INV — Invert input
    values as P1_29.INV
  [5] HYS — Hysteresis.
    0=DISABLE_; 1=ENABLE_
  [4:3] MODE — Selects function mode (on-chip pull-up/pull-down resistor control).
    values as P1_29.MODE
  [2:0] FUNC — Selects pin function for pin P3[25]
    0=P3_25 (General purpose digital input/output pin.); 1=EMC_D_25 (External memory data line 25.); 2=PWM1_2 (Pulse Width Modulator 1, output 2.); 3=T0_MAT0 (Match output for Timer 0, channel 0.)
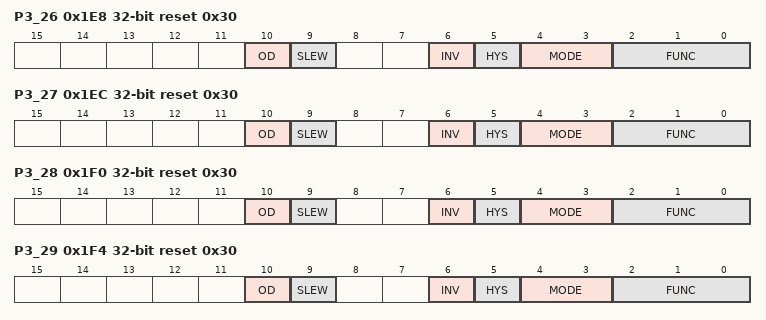
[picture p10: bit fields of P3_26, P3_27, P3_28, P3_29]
0x1E8 P3_26 reset 0x30 — I/O configuration register for pin P3[26]
  [10] OD — Open-drain mode.
    values as P1_29.OD
  [9] SLEW — Driver slew rate
    values as P1_29.SLEW
  [6] INV — Invert input
    values as P1_29.INV
  [5] HYS — Hysteresis.
    0=DISABLE_; 1=ENABLE_
  [4:3] MODE — Selects function mode (on-chip pull-up/pull-down resistor control).
    values as P1_29.MODE
  [2:0] FUNC — Selects pin function for pin P3[26]
    0=P3_26 (General purpose digital input/output pin.); 1=EMC_D_26 (External memory data line 26.); 2=PWM1_3 (Pulse Width Modulator 1, output 3.); 3=T0_MAT1 (Match output for Timer 0, channel 1.); 4=STCLK (System tick timer clock input.)
0x1EC P3_27 reset 0x30 — I/O configuration register for pin P3[27]
  [10] OD — Open-drain mode.
    values as P1_29.OD
  [9] SLEW — Driver slew rate
    values as P1_29.SLEW
  [6] INV — Invert input
    values as P1_29.INV
  [5] HYS — Hysteresis.
    0=DISABLE_; 1=ENABLE_
  [4:3] MODE — Selects function mode (on-chip pull-up/pull-down resistor control).
    values as P1_29.MODE
  [2:0] FUNC — Selects pin function for pin P3[27]
    0=P3_27 (General purpose digital input/output pin.); 1=EMC_D_27 (External memory data line 27.); 2=PWM1_4 (Pulse Width Modulator 1, output 4.); 3=T1_CAP0 (Capture input for Timer 1, channel 0.)
0x1F0 P3_28 reset 0x30 — I/O configuration register for pin P3[28]
  [10] OD — Open-drain mode.
    values as P1_29.OD
  [9] SLEW — Driver slew rate
    values as P1_29.SLEW
  [6] INV — Invert input
    values as P1_29.INV
  [5] HYS — Hysteresis.
    0=DISABLE_; 1=ENABLE_
  [4:3] MODE — Selects function mode (on-chip pull-up/pull-down resistor control).
    values as P1_29.MODE
  [2:0] FUNC — Selects pin function for pin P3[28]
    0=P3_28 (General purpose digital input/output pin.); 1=EMC_D_28 (External memory data line 28.); 2=PWM1_5 (Pulse Width Modulator 1, output 5.); 3=T1_CAP1 (Capture input for Timer 1, channel 1.)
0x1F4 P3_29 reset 0x30 — I/O configuration register for pin P3[29]
  [10] OD — Open-drain mode.
    values as P1_29.OD
  [9] SLEW — Driver slew rate
    values as P1_29.SLEW
  [6] INV — Invert input
    values as P1_29.INV
  [5] HYS — Hysteresis.
    0=DISABLE_; 1=ENABLE_
  [4:3] MODE — Selects function mode (on-chip pull-up/pull-down resistor control).
    values as P1_29.MODE
  [2:0] FUNC — Selects pin function for pin P3[29]
    0=P3_29 (General purpose digital input/output pin.); 1=EMC_D_29 (External memory data line 29.); 2=PWM1_6 (Pulse Width Modulator 1, output 6.); 3=T1_MAT0 (Match output for Timer 1, channel 0.)
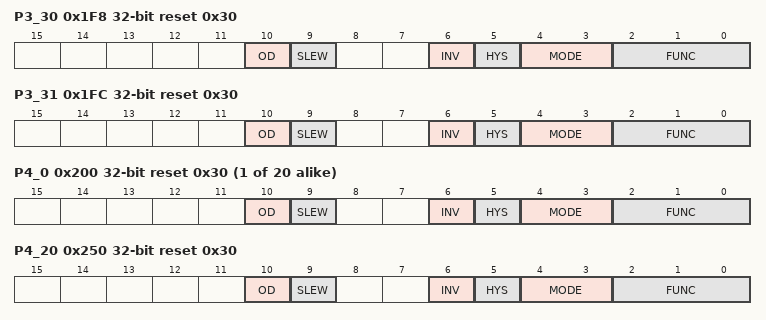
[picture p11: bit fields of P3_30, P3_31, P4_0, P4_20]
0x1F8 P3_30 reset 0x30 — I/O configuration register for pin P3[30]
  [10] OD — Open-drain mode.
    values as P1_29.OD
  [9] SLEW — Driver slew rate
    values as P1_29.SLEW
  [6] INV — Invert input
    values as P1_29.INV
  [5] HYS — Hysteresis.
    0=DISABLE_; 1=ENABLE_
  [4:3] MODE — Selects function mode (on-chip pull-up/pull-down resistor control).
    values as P1_29.MODE
  [2:0] FUNC — Selects pin function for pin P3[30]
    0=P3_30 (General purpose digital input/output pin.); 1=EMC_D_30 (External memory data line 30.); 2=U1_RTS (Request to Send output for UART1. Can also be configured to be an RS-485/EIA-485 output enable signal for UART1.); 3=T1_MAT1 (Match output for Timer 1, channel 1.)
0x1FC P3_31 reset 0x30 — I/O configuration register for pin P3[31]
  [10] OD — Open-drain mode.
    values as P1_29.OD
  [9] SLEW — Driver slew rate
    values as P1_29.SLEW
  [6] INV — Invert input
    values as P1_29.INV
  [5] HYS — Hysteresis.
    0=DISABLE_; 1=ENABLE_
  [4:3] MODE — Selects function mode (on-chip pull-up/pull-down resistor control).
    values as P1_29.MODE
  [2:0] FUNC — Selects pin function for pin P3[31]
    0=P3_31 (General purpose digital input/output pin.); 1=EMC_D_31 (External memory data line 31.); 3=T1_MAT2 (Match output for Timer 1, channel 2.)
{0x200+4i} P4_{i} reset 0x30 (i=0..19) — I/O configuration register for pin P4[{i}]
  [10] OD — Open-drain mode.
    values as P1_29.OD
  [9] SLEW — Driver slew rate
    values as P1_29.SLEW
  [6] INV — Invert input
    values as P1_29.INV
  [5] HYS — Hysteresis.
    0=DISABLE_; 1=ENABLE_
  [4:3] MODE — Selects function mode (on-chip pull-up/pull-down resistor control).
    values as P1_29.MODE
  [2:0] FUNC — Selects pin function for pin P4[{i}]
    0=P4_{i} (General purpose digital input/output pin.); 1=EMC_A_{i} (External memory address line {i}.)
0x250 P4_20 reset 0x30 — I/O configuration register for pin P4[20]
  [10] OD — Open-drain mode.
    values as P1_29.OD
  [9] SLEW — Driver slew rate
    values as P1_29.SLEW
  [6] INV — Invert input
    values as P1_29.INV
  [5] HYS — Hysteresis.
    0=DISABLE_; 1=ENABLE_
  [4:3] MODE — Selects function mode (on-chip pull-up/pull-down resistor control).
    values as P1_29.MODE
  [2:0] FUNC — Selects pin function for pin P4[20]
    0=P4_20 (General purpose digital input/output pin.); 1=EMC_A_20 (External memory address line 20.); 2=I2C2_SDA (I2C2 data input/output (this pin does not use a specialized I2C pad).); 3=SSP1_SCK (Serial Clock for SSP1.)
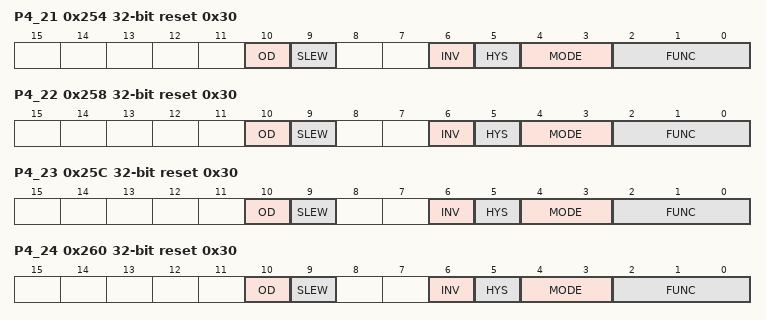
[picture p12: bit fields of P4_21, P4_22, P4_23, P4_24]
0x254 P4_21 reset 0x30 — I/O configuration register for pin P4[21]
  [10] OD — Open-drain mode.
    values as P1_29.OD
  [9] SLEW — Driver slew rate
    values as P1_29.SLEW
  [6] INV — Invert input
    values as P1_29.INV
  [5] HYS — Hysteresis.
    0=DISABLE_; 1=ENABLE_
  [4:3] MODE — Selects function mode (on-chip pull-up/pull-down resistor control).
    values as P1_29.MODE
  [2:0] FUNC — Selects pin function for pin P4[21]
    0=P4_21 (General purpose digital input/output pin.); 1=EMC_A_21 (External memory address line 21.); 2=I2C2_SCL (I2C2 clock input/output (this pin does not use a specialized I2C pad).); 3=SSP1_SSEL (Slave Select for SSP1.)
0x258 P4_22 reset 0x30 — I/O configuration register for pin P4[22]
  [10] OD — Open-drain mode.
    values as P1_29.OD
  [9] SLEW — Driver slew rate
    values as P1_29.SLEW
  [6] INV — Invert input
    values as P1_29.INV
  [5] HYS — Hysteresis.
    0=DISABLE_; 1=ENABLE_
  [4:3] MODE — Selects function mode (on-chip pull-up/pull-down resistor control).
    values as P1_29.MODE
  [2:0] FUNC — Selects pin function for pin P4[22]
    0=P4_22 (General purpose digital input/output pin.); 1=EMC_A_22 (External memory address line 22.); 2=U2_TXD (Transmitter output for UART2.); 3=SSP1_MISO (Master In Slave Out for SSP1.)
0x25C P4_23 reset 0x30 — I/O configuration register for pin P4[23]
  [10] OD — Open-drain mode.
    values as P1_29.OD
  [9] SLEW — Driver slew rate
    values as P1_29.SLEW
  [6] INV — Invert input
    values as P1_29.INV
  [5] HYS — Hysteresis.
    0=DISABLE_; 1=ENABLE_
  [4:3] MODE — Selects function mode (on-chip pull-up/pull-down resistor control).
    values as P1_29.MODE
  [2:0] FUNC — Selects pin function for pin P4[23]
    0=P4_23 (General purpose digital input/output pin.); 1=EMC_A_23 (External memory address line 23.); 2=U2_RXD (Receiver input for UART2.); 3=SSP1_MOSI (Master Out Slave In for SSP1.)
0x260 P4_24 reset 0x30 — I/O configuration register for pin P4[24]
  [10] OD — Open-drain mode.
    values as P1_29.OD
  [9] SLEW — Driver slew rate
    values as P1_29.SLEW
  [6] INV — Invert input
    values as P1_29.INV
  [5] HYS — Hysteresis.
    0=DISABLE_; 1=ENABLE_
  [4:3] MODE — Selects function mode (on-chip pull-up/pull-down resistor control).
    values as P1_29.MODE
  [2:0] FUNC — Selects pin function for pin P4[24]
    0=P4_24 (General purpose digital input/output pin.); 1=EMC_OE (LOW active Output Enable signal.)
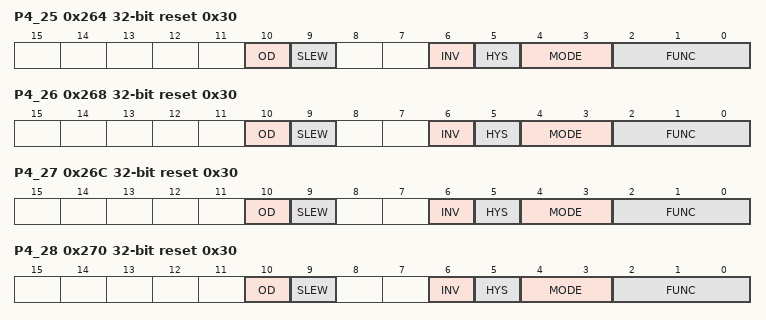
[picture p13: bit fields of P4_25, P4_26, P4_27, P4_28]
0x264 P4_25 reset 0x30 — I/O configuration register for pin P4[25]
  [10] OD — Open-drain mode.
    values as P1_29.OD
  [9] SLEW — Driver slew rate
    values as P1_29.SLEW
  [6] INV — Invert input
    values as P1_29.INV
  [5] HYS — Hysteresis.
    0=DISABLE_; 1=ENABLE_
  [4:3] MODE — Selects function mode (on-chip pull-up/pull-down resistor control).
    values as P1_29.MODE
  [2:0] FUNC — Selects pin function for pin P4[25]
    0=P4_25 (General purpose digital input/output pin.); 1=EMC_WE (LOW active Write Enable signal.)
0x268 P4_26 reset 0x30 — I/O configuration register for pin P4[26]
  [10] OD — Open-drain mode.
    values as P1_29.OD
  [9] SLEW — Driver slew rate
    values as P1_29.SLEW
  [6] INV — Invert input
    values as P1_29.INV
  [5] HYS — Hysteresis.
    0=DISABLE_; 1=ENABLE_
  [4:3] MODE — Selects function mode (on-chip pull-up/pull-down resistor control).
    values as P1_29.MODE
  [2:0] FUNC — Selects pin function for pin P4[26]
    0=P4_26 (General purpose digital input/output pin.); 1=EMC_BLS0 (LOW active Byte Lane select signal 0.)
0x26C P4_27 reset 0x30 — I/O configuration register for pin P4[27]
  [10] OD — Open-drain mode.
    values as P1_29.OD
  [9] SLEW — Driver slew rate
    values as P1_29.SLEW
  [6] INV — Invert input
    values as P1_29.INV
  [5] HYS — Hysteresis.
    0=DISABLE_; 1=ENABLE_
  [4:3] MODE — Selects function mode (on-chip pull-up/pull-down resistor control).
    values as P1_29.MODE
  [2:0] FUNC — Selects pin function for pin P4[27]
    0=P4_27 (General purpose digital input/output pin.); 1=EMC_BLS1 (LOW active Byte Lane select signal 1.)
0x270 P4_28 reset 0x30 — I/O configuration register for pin P4[28]
  [10] OD — Open-drain mode.
    values as P1_29.OD
  [9] SLEW — Driver slew rate
    values as P1_29.SLEW
  [6] INV — Invert input
    values as P1_29.INV
  [5] HYS — Hysteresis.
    0=DISABLE_; 1=ENABLE_
  [4:3] MODE — Selects function mode (on-chip pull-up/pull-down resistor control).
    values as P1_29.MODE
  [2:0] FUNC — Selects pin function for pin P4[28]
    0=P4_28 (General purpose digital input/output pin.); 1=EMC_BLS2 (LOW active Byte Lane select signal 2.); 2=U3_TXD (Transmitter output for UART3.); 3=T2_MAT0 (Match output for Timer 2, channel 0.); 5=LCD_VD_6 (LCD data.); 6=LCD_VD_10 (LCD data.); 7=LCD_VD_2 (LCD data.)
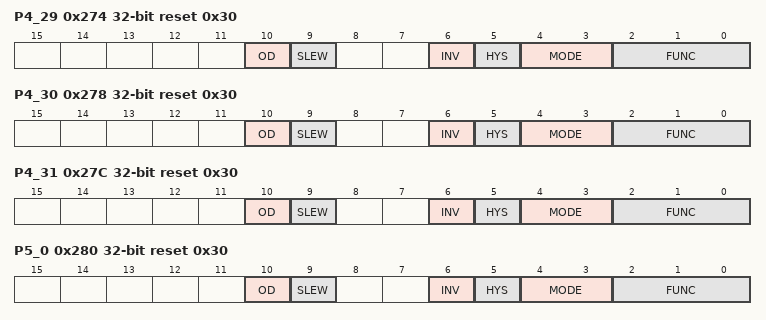
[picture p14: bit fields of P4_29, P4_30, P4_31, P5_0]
0x274 P4_29 reset 0x30 — I/O configuration register for pin P4[29]
  [10] OD — Open-drain mode.
    values as P1_29.OD
  [9] SLEW — Driver slew rate
    values as P1_29.SLEW
  [6] INV — Invert input
    values as P1_29.INV
  [5] HYS — Hysteresis.
    0=DISABLE_; 1=ENABLE_
  [4:3] MODE — Selects function mode (on-chip pull-up/pull-down resistor control).
    values as P1_29.MODE
  [2:0] FUNC — Selects pin function for pin P4[29]
    0=P4_29 (General purpose digital input/output pin.); 1=EMC_BLS3 (LOW active Byte Lane select signal 3.); 2=U3_RXD (Receiver input for UART3.); 3=T2_MAT1 (Match output for Timer 2, channel 1.); 4=I2C2_SCL (I2C2 clock input/output (this pin does not use a specialized I2C pad).); 5=LCD_VD_7 (LCD data.); 6=LCD_VD_11 (LCD data.); 7=LCD_VD_3 (LCD data.)
0x278 P4_30 reset 0x30 — I/O configuration register for pin P4[30]
  [10] OD — Open-drain mode.
    values as P1_29.OD
  [9] SLEW — Driver slew rate
    values as P1_29.SLEW
  [6] INV — Invert input
    values as P1_29.INV
  [5] HYS — Hysteresis.
    0=DISABLE_; 1=ENABLE_
  [4:3] MODE — Selects function mode (on-chip pull-up/pull-down resistor control).
    values as P1_29.MODE
  [2:0] FUNC — Selects pin function for pin P4[30]
    0=P4_30 (General purpose digital input/output pin.); 1=EMC_CS0 (LOW active Chip Select 0 signal.); 5=CMP0_OUT (Comparator 0, output.)
0x27C P4_31 reset 0x30 — I/O configuration register for pin P4[31]
  [10] OD — Open-drain mode.
    values as P1_29.OD
  [9] SLEW — Driver slew rate
    values as P1_29.SLEW
  [6] INV — Invert input
    values as P1_29.INV
  [5] HYS — Hysteresis.
    0=DISABLE_; 1=ENABLE_
  [4:3] MODE — Selects function mode (on-chip pull-up/pull-down resistor control).
    values as P1_29.MODE
  [2:0] FUNC — Selects pin function for pin P4[31]
    0=P4_31 (General purpose digital input/output pin.); 1=EMC_CS1 (LOW active Chip Select 1 signal.)
0x280 P5_0 reset 0x30 — I/O configuration register for pin P5[0]
  [10] OD — Open-drain mode.
    values as P1_29.OD
  [9] SLEW — Driver slew rate
    values as P1_29.SLEW
  [6] INV — Invert input
    values as P1_29.INV
  [5] HYS — Hysteresis.
    0=DISABLE_; 1=ENABLE_
  [4:3] MODE — Selects function mode (on-chip pull-up/pull-down resistor control).
    values as P1_29.MODE
  [2:0] FUNC — Selects pin function for pin P5[0]
    0=P5_0 (General purpose digital input/output pin.); 1=EMC_A_24 (External memory address line 24.); 2=SSP2_MOSI (Master Out Slave In for SSP2.); 3=T2_MAT2 (Match output for Timer 2, channel 2.)
0x284 P5_1 reset 0x30 — I/O configuration register for pin P5[1]
  [10] OD — Open-drain mode.
    values as P1_29.OD
  [9] SLEW — Driver slew rate
    values as P1_29.SLEW
  [6] INV — Invert input
    values as P1_29.INV
  [5] HYS — Hysteresis.
    0=DISABLE_; 1=ENABLE_
  [4:3] MODE — Selects function mode (on-chip pull-up/pull-down resistor control).
    values as P1_29.MODE
  [2:0] FUNC — Selects pin function for pin P5[1]
    0=P5_1 (General purpose digital input/output pin.); 1=EMC_A_25 (External memory address line 25.); 2=SSP2_MISO (Master In Slave Out for SSP2.); 3=T2_MAT3 (Match output for Timer 2, channel 3.)
0x288 P5_2 reset 0x80 — I/O configuration register for pin P5[2]
  [9] HIDRIVE — Controls sink current capability of the pin, only for P5[2] and P5[3].
    0=LOWDRIVE (Output drive sink is 4 mA. This is sufficient for standard and fast mode I2C.); 1=HIGHDRIVE (Output drive sink is 20 mA. This is needed for Fast Mode Plus I2C. Refer to the appropriate specific device data sheet for details.)
  [8] HS — Configures I2C features for standard mode, fast mode, and Fast Mode Plus operation.
    0=ENABLED (I2C 50ns glitch filter and slew rate control enabled.); 1=DISABLED (I2C 50ns glitch filter and slew rate control disabled.)
  [6] INV — Invert input
    values as P1_29.INV
  [2:0] FUNC — Selects pin function for pin P5[2]
    0=P5_2 (General purpose digital input/output pin.); 3=T3_MAT2 (Match output for Timer 3, channel 2.); 5=I2C0_SDA (I2C0 data input/output (this pin uses a specialized I2C pad that supports I2C Fast Mode Plus).)
0x28C P5_3 reset 0x80 — I/O configuration register for pin P5[3]
  [9] HIDRIVE — Controls sink current capability of the pin, only for P5[2] and P5[3].
    values as P5_2.HIDRIVE
  [8] HS — Configures I2C features for standard mode, fast mode, and Fast Mode Plus operation.
    values as P5_2.HS
  [6] INV — Invert input
    values as P1_29.INV
  [2:0] FUNC — Selects pin function for pin P5[3]
    0=P5_3 (General purpose digital input/output pin.); 4=U4_RXD (Receiver input for USART4.); 5=I2C0_SCL (I2C0 clock input/output (this pin uses a specialized I2C pad that supports I2C Fast Mode Plus.)
0x290 P5_4 reset 0x30 — I/O configuration register for pin P5[4]
  [10] OD — Open-drain mode.
    values as P1_29.OD
  [9] SLEW — Driver slew rate
    values as P1_29.SLEW
  [6] INV — Invert input
    values as P1_29.INV
  [5] HYS — Hysteresis.
    0=DISABLE_; 1=ENABLE_
  [4:3] MODE — Selects function mode (on-chip pull-up/pull-down resistor control).
    values as P1_29.MODE
  [2:0] FUNC — Selects pin function for pin P5[4]
    0=P5_4 (General purpose digital input/output pin.); 1=U0_OE (RS-485/EIA-485 output enable signal for UART0.); 3=T3_MAT3 (Match output for Timer 3, channel 3.); 4=U4_TXD (Transmitter output for USART4 (input/output in smart card mode).)
